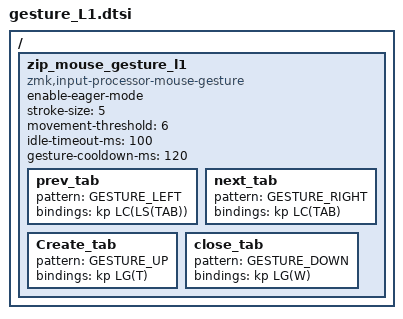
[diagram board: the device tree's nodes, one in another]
// Mac用ジェスジャー
/ {
  zip_mouse_gesture_l1: zip_mouse_gesture_l1 {
    compatible = "zmk,input-processor-mouse-gesture";
    enable-eager-mode;
    stroke-size = <5>;
    movement-threshold = <6>;
    idle-timeout-ms = <100>;
    gesture-cooldown-ms = <120>;

    prev_tab    { pattern = <GESTURE_LEFT>;  bindings = <&kp LC(LS(TAB))>; }; // 前のタブ
    next_tab    { pattern = <GESTURE_RIGHT>; bindings = <&kp LC(TAB)>;     }; // 次のタブ
    Create_tab  { pattern = <GESTURE_UP>;    bindings = <&kp LG(T)>;      }; // タブを作成
    close_tab   { pattern = <GESTURE_DOWN>;  bindings = <&kp LG(W)>;       }; // タブを閉じる
  };
};
